# TC37XPD register map
Vendor: Infineon; Series: ATVMC; File version: 100
CPU: other r0p0, little endian, MPU, FPU, vendor SysTick, 4 interrupt priority bits
Registers are 32-bit, read-write, reset 0x0 unless marked. A register's access mark holds for its fields unless they carry their own. Offsets are from the block's base; [hi:lo] are bit positions; lines under a group give offsets from that group; {n}, {i} and the like mark numbered series; 'fields as' and 'values as' point back to an identical list.

## GETH (part 3 of 7)
Base 0xF001D000
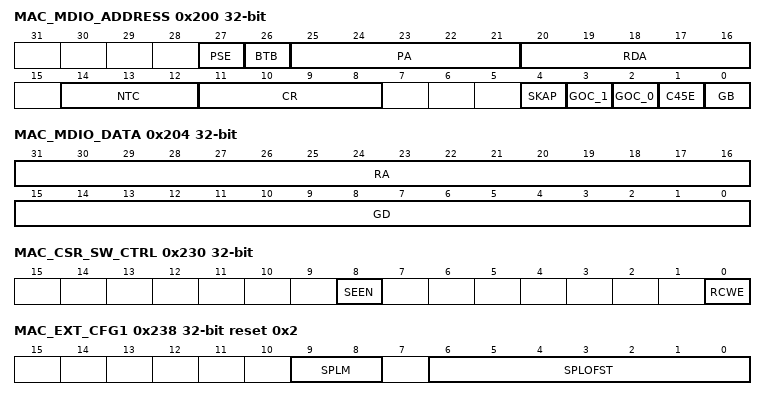
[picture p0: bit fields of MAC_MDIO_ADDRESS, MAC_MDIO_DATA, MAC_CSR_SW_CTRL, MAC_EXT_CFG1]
0x200 MAC_MDIO_ADDRESS — MAC MDIO Address Register resetvalue={Application Reset:0x0}
  [27] PSE — Preamble Suppression Enable PSE. When this bit is set the SMA suppresses the 32 bit preamble and transmits MDIO frames with only 1 preamble bit. When this bit is 0 the MDIO frame always has 32 bits of preamble as defined in the IEEE specifications. Value After Reset 0x0
  [26] BTB — Back to Back transactions BTB. When this bit is set and the NTC has value greater than 0 then the MAC informs the completion of a read or write command at the end of frame transfer before the trailing clocks are transmitted . The software can thus initiate the next command which is executed immediately irrespective of the number trailing clocks generated for the previous frame. When this bit is reset then the read write command completion GB is cleared only after the trailing clocks are generated. In this mode it is ensured that the NTC is always generated after each frame. This bit must not be set when NTC 0. Value After Reset 0x0
  [25:21] PA — Physical Layer Address PA. This field indicates which Clause 22 PHY devices out of 32 devices the MAC is accessing. This field indicates which Clause 45 capable PHYs out of 32 PHYs the MAC is accessing. Value After Reset 0x0
  [20:16] RDA — Register Device Address RDA. These bits select the PHY register in selected Clause 22 PHY device. These bits select the Device MMD in selected Clause 45 capable PHY. Value After Reset 0x0
  [14:12] NTC — Number of Trailing Clocks NTC. This field controls the number of trailing clock cycles generated on gmii mdc o MDC after the end of transmission of MDIO frame. The valid values can be from 0 to 7. Programming the value to 3 h3 indicates that there are additional three clock cycles on the MDC line after the end of MDIO frame transfer. Value After Reset 0x0
  [11:8] CR — CSR Clock Range CR. The CSR Clock Range selection determines the frequency of the MDC clock according to the CSR clock frequency used in your design 0110 0111 Reserved The suggested range of CSR clock frequency applicable for each value when Bit 11 0 ensures that the MDC clock is approximately between 1.0 MHz to 2.5 MHz frequency range. When Bit 11 is set you can achieve a higher frequency of the MDC clock than the frequency limit of 2.5 MHz specified in the IEEE 802.3 and program a clock divider of lower value. For example when CSR clock is of 100 MHz frequency and you program these bits as 1010 the resultant MDC clock is of 12.5 MHz which is above the range specified in IEEE 802.3. Program the following values only if the interfacing chips support faster MDC clocks These bits are not used for accessing RevMII. These bits are read only if the RevMII interface is selected as single PHY interface. Value After Reset 0x0
  [4] SKAP — Skip Address Packet SKAP. When this bit is set the SMA does not send the address packets before read write or post read increment address packets. This bit is valid only when C45E is set. Value After Reset 0x0
  [3] GOC_1 — GMII Operation Command 1 GOC 1. This bit is higher bit of the operation command to the PHY or RevMII GOC 1 and GOC O is encoded as follows 00 Reserved 01 Write 10 Post Read Increment Address for Clause 45 PHY 11 Read When Clause 22 PHY or RevMII is enabled only Write and Read commands are valid. Value After Reset 0x0
  [2] GOC_0 — GMII Operation Command 0 GOC 0. This is the lower bit of the operation command to the PHY or RevMII. When in SMA mode MDIO master this bit along with GOC 1 determines the operation to be performed to the PHY. When only RevMII is selected in configuration this bit is read only and tied to 1. Value After Reset 0x0
  [1] C45E — Clause 45 PHY Enable C45E. When this bit is set Clause 45 capable PHY is connected to MDIO. When this bit is reset Clause 22 capable PHY is connected to MDIO. Value After Reset 0x0
  [0] GB — GMII Busy GB. The application sets this bit to instruct the SMA to initiate a Read or Write access to the MDIO slave. The MAC clears this bit after the MDIO frame transfer is completed. Hence the software must not write or change any of the fields in MAC MDIO Address and MAC MDIO Data registers as long as this bit is set. For write transfers the application must first write 16 bit data in the GDl field and also RA field when C45E is set in MAC MDIO Data register before setting this bit. When C45E is set it should also write into the RA field of MAC MDIO Data register before initiating a read transfer. When a read transfer is completed GB 0 the data read from the PHY register is valid in the GD field of the MAC MDIO Data register. Note Even if the addressed PHY is not present there is no change in the functionality of this bit. Access restriction applies. Setting 1 sets. Self cleared. Setting 0 has no effect. Value After Reset 0x0
0x204 MAC_MDIO_DATA — MAC MDIO Data Register resetvalue={Application Reset:0x0}
  [31:16] RA — Register Address RA. This field is valid only when C45E is set. It contains the Register Address in the PHY to which the MDIO frame is intended for. Value After Reset 0x0
  [15:0] GD — GMII Data GD. This field contains the 16 bit data value read from the PHY or RevMII after a Management Read operation or the 16 bit data value to be written to the PHY or RevMII before a Management Write operation. Value After Reset 0x0
0x230 MAC_CSR_SW_CTRL — MAC CSR Software Controls Register resetvalue={Application Reset:0x0}
  [8] SEEN — Slave Error Response Enable SEEN. When this bit is set the MAC responds with Slave Error for accesses to reserved registers in CSR space. When this bit is reset the MAC responds with Okay response to any register accessed from CSR space. Value After Reset 0x0
  [0] RCWE — Register Clear on Write 1 Enable RCWE . When this bit is set the access mode of some register fields changes to Clear on Write 1 the application needs to set that respective bit to 1 to clear it. When this bit is reset the access mode of these register fields remain as Clear on Read. Value After Reset 0x0
0x238 MAC_EXT_CFG1 reset 0x2 — MAC Extended Configuration Register 1 resetvalue={Application Reset:0x2}
  [9:8] SPLM — Split Mode SPLM. These bits indicate the mode of splitting the incoming Rx packets. They are
  [6:0] SPLOFST — Split Offset SPLOFST. These bits indicate the value of offset from the beginning of Length Type field at which header split should take place when the appropriate SPLM is selected. The reset value of this field is 2 bytes indicating a split at L2 header. Value is in terms ofbytes.
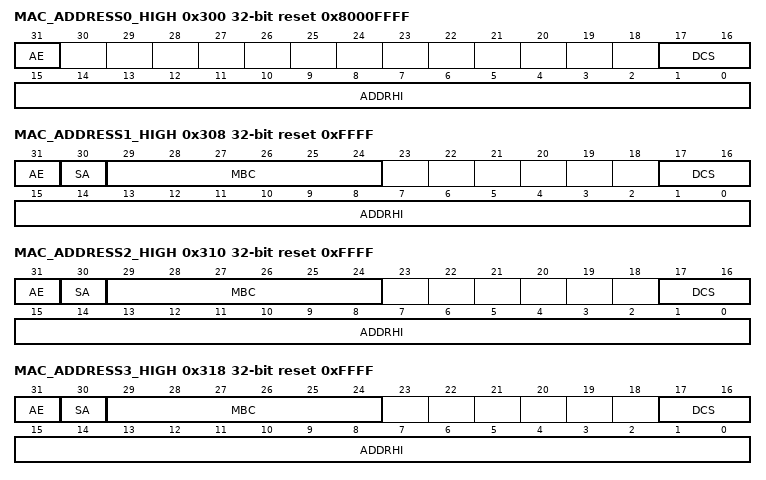
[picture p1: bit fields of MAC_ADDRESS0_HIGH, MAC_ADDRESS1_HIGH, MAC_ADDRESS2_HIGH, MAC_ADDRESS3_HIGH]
0x300 MAC_ADDRESS0_HIGH access per field reset 0x8000FFFF — MAC Address 0 High Register resetvalue={Application Reset:0x08000FFFF}
  [31] AE ro — Address Enable AE. This bit is always set to 1. Value After Reset 0x1
  [17:16] DCS rw — DMA Channel Select DCS. If the PDC bit of MAC Ext Configuration register is not set This field contains the binary representation of the DMA Channel number to which an Rx packet whose DA matches the MAC Address0 content is routed. If the PDC bit of MAC Ext Configuration register is set This field contains the one hot representation of one or more DMA Channel numbers to which an Rx packet whose DA matches the MAC Address0 content is routed.
  [15:0] ADDRHI rw — MAC Address0 47 32 ADDRHI. This field contains the upper 16 bits 47 32 of the first 6 byte MAC address. The MAC uses this field for filtering the received packets and inserting the MAC address in the Transmit Flow Control Pause Packets. Value After Reset 0xffff
0x304 MAC_ADDRESS0_LOW reset 0xFFFFFFFF — MAC Address 0 Low Register resetvalue={Application Reset:0x0FFFFFFFF}
  [31:0] ADDRLO — MAC Address0 31 0 ADDRLO. This field contains the lower 32 bits of the first 6 byte MAC address. The MAC uses this field for filtering the received packets and inserting the MAC address in the Transmit Flow Control Pause Packets. Value After Reset 0xffffffff
0x308 MAC_ADDRESS1_HIGH reset 0xFFFF — MAC Address 31 High Register resetvalue={Application Reset:0x0FFFF}
  [31] AE — Address Enable AE. When this bit is set the address filter module uses the second MAC address for perfect filtering. When this bit is reset the address filter module ignores the address for filtering. Value After Reset 0x0
  [30] SA — Source Address SA. When this bit is set the MAC Address1 47 0 is used to compare with the SA fields of the received packet. When this bit is reset the MAC Address1 47 0 is used to compare with the DA fields of the received packet. Value After Reset 0x0
  [29:24] MBC — Mask Byte Control MBC. These bits are mask control bits for comparing each of the MAC Address bytes. When set high the MAC does not compare the corresponding byte of received DA or SA with the contents of MAC Address1 registers. Each bit controls the masking of the bytes as follows Bit 29 Register 194 15 8 Bit 28 Register 194 7 0 Bit 27 Register 195 31 24 Bit 24 Register 195 7 0 You can filter a group of addresses known as group address filtering by masking one or more bytes of the address. Value After Reset 0x0
  [17:16] DCS — DMA Channel Select DCS. If the PDC bit of MAC Ext Configuration register is not set This field contains the binary representation of the DMA Channel number to which an Rx packet whose DA matches the MAC Address0 content is routed. If the PDC bit of MAC Ext Configuration register is set This field contains the one hot representation of one or more DMA Channel numbers to which an Rx packet whose DA matches the MAC Address0 content is routed.
  [15:0] ADDRHI — MAC Address1 47 32 ADDRHI. This field contains the upper 16 bits 47 32 of the second 6 byte MAC address. Value After Reset 0xffff
0x30C MAC_ADDRESS1_LOW reset 0xFFFFFFFF — MAC Address 31 Low Register resetvalue={Application Reset:0x0FFFFFFFF}
  [31:0] ADDRLO — MAC Address1 31 0 ADDRLO. This field contains the lower 32 bits of second 6 byte MAC address. The content of this field is undefined until loaded by the application after the initialization process. Value After Reset 0xffffffff
0x310 MAC_ADDRESS2_HIGH reset 0xFFFF — MAC Address 31 High Register resetvalue={Application Reset:0x0FFFF}
  fields as MAC_ADDRESS1_HIGH
0x314 MAC_ADDRESS2_LOW reset 0xFFFFFFFF — MAC Address 31 Low Register resetvalue={Application Reset:0x0FFFFFFFF}
  fields as MAC_ADDRESS1_LOW
0x318 MAC_ADDRESS3_HIGH reset 0xFFFF — MAC Address 31 High Register resetvalue={Application Reset:0x0FFFF}
  fields as MAC_ADDRESS1_HIGH
0x31C MAC_ADDRESS3_LOW reset 0xFFFFFFFF — MAC Address 31 Low Register resetvalue={Application Reset:0x0FFFFFFFF}
  fields as MAC_ADDRESS1_LOW
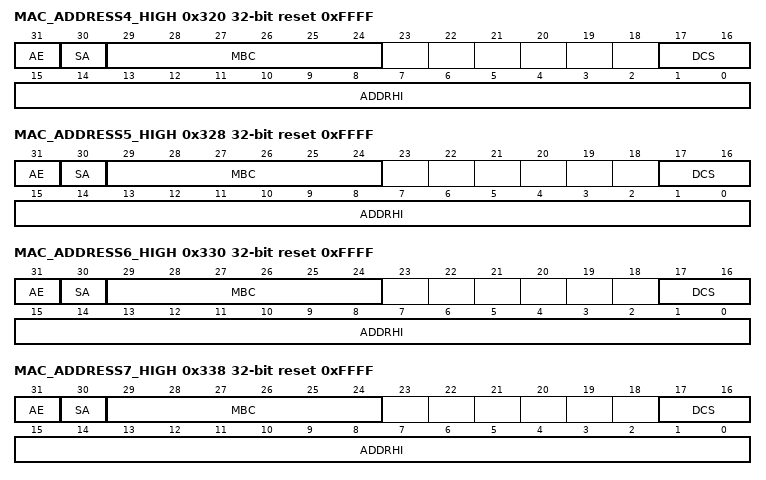
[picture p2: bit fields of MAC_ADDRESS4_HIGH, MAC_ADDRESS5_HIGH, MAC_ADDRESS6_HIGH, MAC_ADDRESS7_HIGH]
0x320 MAC_ADDRESS4_HIGH reset 0xFFFF — MAC Address 31 High Register resetvalue={Application Reset:0x0FFFF}
  fields as MAC_ADDRESS1_HIGH
0x324 MAC_ADDRESS4_LOW reset 0xFFFFFFFF — MAC Address 31 Low Register resetvalue={Application Reset:0x0FFFFFFFF}
  fields as MAC_ADDRESS1_LOW
0x328 MAC_ADDRESS5_HIGH reset 0xFFFF — MAC Address 31 High Register resetvalue={Application Reset:0x0FFFF}
  fields as MAC_ADDRESS1_HIGH
0x32C MAC_ADDRESS5_LOW reset 0xFFFFFFFF — MAC Address 31 Low Register resetvalue={Application Reset:0x0FFFFFFFF}
  fields as MAC_ADDRESS1_LOW
0x330 MAC_ADDRESS6_HIGH reset 0xFFFF — MAC Address 31 High Register resetvalue={Application Reset:0x0FFFF}
  fields as MAC_ADDRESS1_HIGH
0x334 MAC_ADDRESS6_LOW reset 0xFFFFFFFF — MAC Address 31 Low Register resetvalue={Application Reset:0x0FFFFFFFF}
  fields as MAC_ADDRESS1_LOW
0x338 MAC_ADDRESS7_HIGH reset 0xFFFF — MAC Address 31 High Register resetvalue={Application Reset:0x0FFFF}
  fields as MAC_ADDRESS1_HIGH
0x33C MAC_ADDRESS7_LOW reset 0xFFFFFFFF — MAC Address 31 Low Register resetvalue={Application Reset:0x0FFFFFFFF}
  fields as MAC_ADDRESS1_LOW
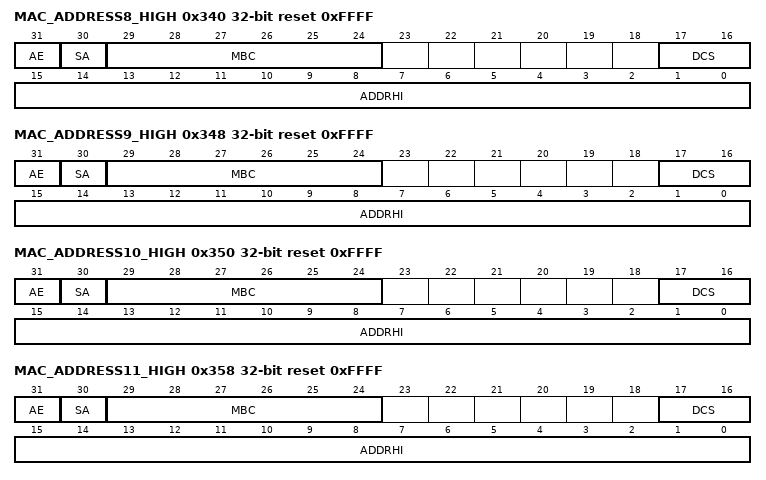
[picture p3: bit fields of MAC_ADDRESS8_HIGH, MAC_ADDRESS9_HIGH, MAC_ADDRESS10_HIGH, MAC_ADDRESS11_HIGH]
0x340 MAC_ADDRESS8_HIGH reset 0xFFFF — MAC Address 31 High Register resetvalue={Application Reset:0x0FFFF}
  fields as MAC_ADDRESS1_HIGH
0x344 MAC_ADDRESS8_LOW reset 0xFFFFFFFF — MAC Address 31 Low Register resetvalue={Application Reset:0x0FFFFFFFF}
  fields as MAC_ADDRESS1_LOW
0x348 MAC_ADDRESS9_HIGH reset 0xFFFF — MAC Address 31 High Register resetvalue={Application Reset:0x0FFFF}
  fields as MAC_ADDRESS1_HIGH
0x34C MAC_ADDRESS9_LOW reset 0xFFFFFFFF — MAC Address 31 Low Register resetvalue={Application Reset:0x0FFFFFFFF}
  fields as MAC_ADDRESS1_LOW
0x350 MAC_ADDRESS10_HIGH reset 0xFFFF — MAC Address 31 High Register resetvalue={Application Reset:0x0FFFF}
  fields as MAC_ADDRESS1_HIGH
0x354 MAC_ADDRESS10_LOW reset 0xFFFFFFFF — MAC Address 31 Low Register resetvalue={Application Reset:0x0FFFFFFFF}
  fields as MAC_ADDRESS1_LOW
0x358 MAC_ADDRESS11_HIGH reset 0xFFFF — MAC Address 31 High Register resetvalue={Application Reset:0x0FFFF}
  fields as MAC_ADDRESS1_HIGH
0x35C MAC_ADDRESS11_LOW reset 0xFFFFFFFF — MAC Address 31 Low Register resetvalue={Application Reset:0x0FFFFFFFF}
  fields as MAC_ADDRESS1_LOW
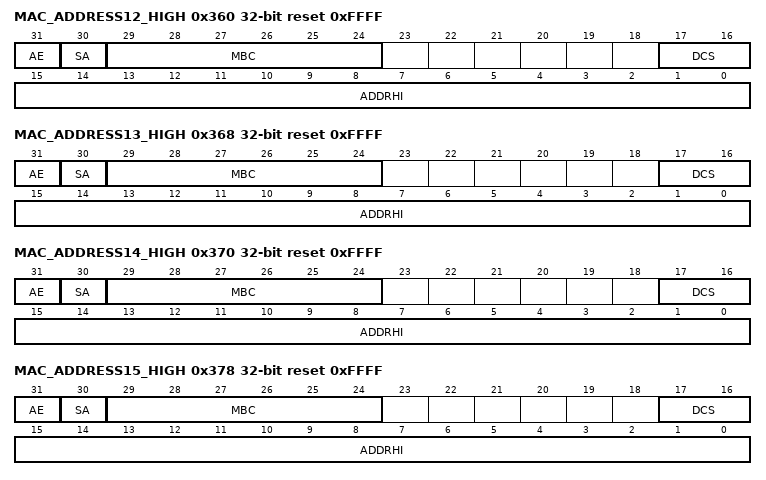
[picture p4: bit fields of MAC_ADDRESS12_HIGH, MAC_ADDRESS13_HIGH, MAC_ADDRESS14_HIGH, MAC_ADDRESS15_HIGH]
0x360 MAC_ADDRESS12_HIGH reset 0xFFFF — MAC Address 31 High Register resetvalue={Application Reset:0x0FFFF}
  fields as MAC_ADDRESS1_HIGH
0x364 MAC_ADDRESS12_LOW reset 0xFFFFFFFF — MAC Address 31 Low Register resetvalue={Application Reset:0x0FFFFFFFF}
  fields as MAC_ADDRESS1_LOW
0x368 MAC_ADDRESS13_HIGH reset 0xFFFF — MAC Address 31 High Register resetvalue={Application Reset:0x0FFFF}
  fields as MAC_ADDRESS1_HIGH
0x36C MAC_ADDRESS13_LOW reset 0xFFFFFFFF — MAC Address 31 Low Register resetvalue={Application Reset:0x0FFFFFFFF}
  fields as MAC_ADDRESS1_LOW
0x370 MAC_ADDRESS14_HIGH reset 0xFFFF — MAC Address 31 High Register resetvalue={Application Reset:0x0FFFF}
  fields as MAC_ADDRESS1_HIGH
0x374 MAC_ADDRESS14_LOW reset 0xFFFFFFFF — MAC Address 31 Low Register resetvalue={Application Reset:0x0FFFFFFFF}
  fields as MAC_ADDRESS1_LOW
0x378 MAC_ADDRESS15_HIGH reset 0xFFFF — MAC Address 31 High Register resetvalue={Application Reset:0x0FFFF}
  fields as MAC_ADDRESS1_HIGH
0x37C MAC_ADDRESS15_LOW reset 0xFFFFFFFF — MAC Address 31 Low Register resetvalue={Application Reset:0x0FFFFFFFF}
  fields as MAC_ADDRESS1_LOW
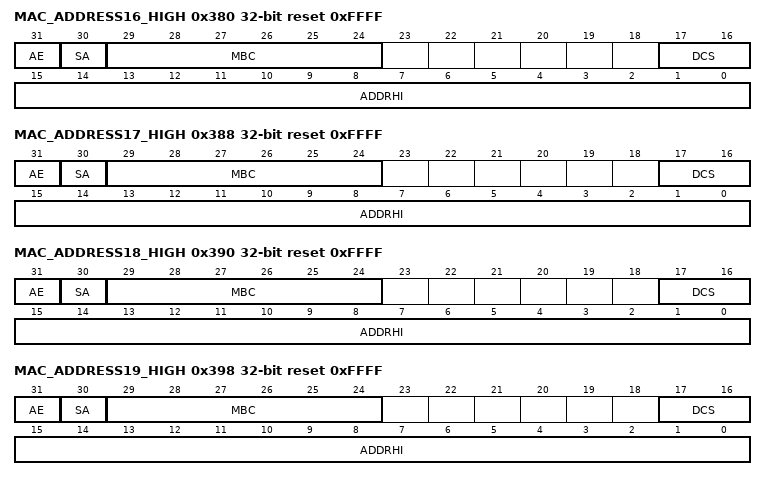
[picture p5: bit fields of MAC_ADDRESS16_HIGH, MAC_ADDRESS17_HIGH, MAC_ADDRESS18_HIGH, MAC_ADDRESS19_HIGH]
0x380 MAC_ADDRESS16_HIGH reset 0xFFFF — MAC Address 31 High Register resetvalue={Application Reset:0x0FFFF}
  fields as MAC_ADDRESS1_HIGH
0x384 MAC_ADDRESS16_LOW reset 0xFFFFFFFF — MAC Address 31 Low Register resetvalue={Application Reset:0x0FFFFFFFF}
  fields as MAC_ADDRESS1_LOW
0x388 MAC_ADDRESS17_HIGH reset 0xFFFF — MAC Address 31 High Register resetvalue={Application Reset:0x0FFFF}
  fields as MAC_ADDRESS1_HIGH
0x38C MAC_ADDRESS17_LOW reset 0xFFFFFFFF — MAC Address 31 Low Register resetvalue={Application Reset:0x0FFFFFFFF}
  fields as MAC_ADDRESS1_LOW
0x390 MAC_ADDRESS18_HIGH reset 0xFFFF — MAC Address 31 High Register resetvalue={Application Reset:0x0FFFF}
  fields as MAC_ADDRESS1_HIGH
0x394 MAC_ADDRESS18_LOW reset 0xFFFFFFFF — MAC Address 31 Low Register resetvalue={Application Reset:0x0FFFFFFFF}
  fields as MAC_ADDRESS1_LOW
0x398 MAC_ADDRESS19_HIGH reset 0xFFFF — MAC Address 31 High Register resetvalue={Application Reset:0x0FFFF}
  fields as MAC_ADDRESS1_HIGH
0x39C MAC_ADDRESS19_LOW reset 0xFFFFFFFF — MAC Address 31 Low Register resetvalue={Application Reset:0x0FFFFFFFF}
  fields as MAC_ADDRESS1_LOW
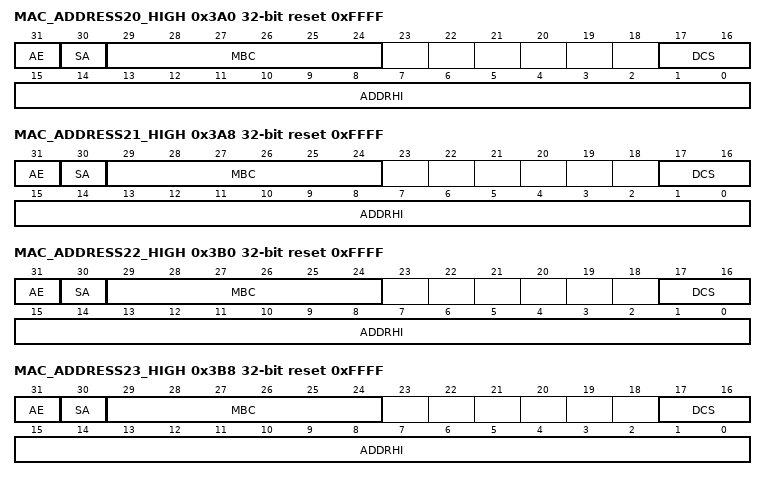
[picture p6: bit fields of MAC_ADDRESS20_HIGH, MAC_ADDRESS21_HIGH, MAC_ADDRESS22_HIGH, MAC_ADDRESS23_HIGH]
0x3A0 MAC_ADDRESS20_HIGH reset 0xFFFF — MAC Address 31 High Register resetvalue={Application Reset:0x0FFFF}
  fields as MAC_ADDRESS1_HIGH
0x3A4 MAC_ADDRESS20_LOW reset 0xFFFFFFFF — MAC Address 31 Low Register resetvalue={Application Reset:0x0FFFFFFFF}
  fields as MAC_ADDRESS1_LOW
0x3A8 MAC_ADDRESS21_HIGH reset 0xFFFF — MAC Address 31 High Register resetvalue={Application Reset:0x0FFFF}
  fields as MAC_ADDRESS1_HIGH
0x3AC MAC_ADDRESS21_LOW reset 0xFFFFFFFF — MAC Address 31 Low Register resetvalue={Application Reset:0x0FFFFFFFF}
  fields as MAC_ADDRESS1_LOW
0x3B0 MAC_ADDRESS22_HIGH reset 0xFFFF — MAC Address 31 High Register resetvalue={Application Reset:0x0FFFF}
  fields as MAC_ADDRESS1_HIGH
0x3B4 MAC_ADDRESS22_LOW reset 0xFFFFFFFF — MAC Address 31 Low Register resetvalue={Application Reset:0x0FFFFFFFF}
  fields as MAC_ADDRESS1_LOW
0x3B8 MAC_ADDRESS23_HIGH reset 0xFFFF — MAC Address 31 High Register resetvalue={Application Reset:0x0FFFF}
  fields as MAC_ADDRESS1_HIGH
0x3BC MAC_ADDRESS23_LOW reset 0xFFFFFFFF — MAC Address 31 Low Register resetvalue={Application Reset:0x0FFFFFFFF}
  fields as MAC_ADDRESS1_LOW
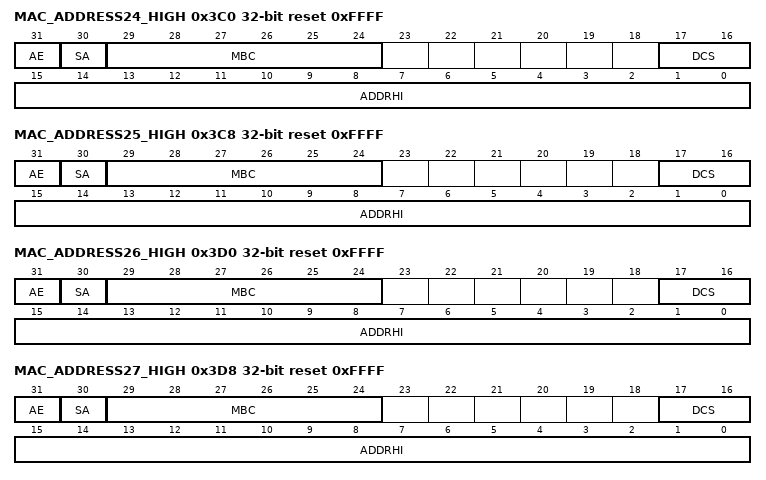
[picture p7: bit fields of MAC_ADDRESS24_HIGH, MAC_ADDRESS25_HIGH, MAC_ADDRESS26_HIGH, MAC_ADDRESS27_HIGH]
0x3C0 MAC_ADDRESS24_HIGH reset 0xFFFF — MAC Address 31 High Register resetvalue={Application Reset:0x0FFFF}
  fields as MAC_ADDRESS1_HIGH
0x3C4 MAC_ADDRESS24_LOW reset 0xFFFFFFFF — MAC Address 31 Low Register resetvalue={Application Reset:0x0FFFFFFFF}
  fields as MAC_ADDRESS1_LOW
0x3C8 MAC_ADDRESS25_HIGH reset 0xFFFF — MAC Address 31 High Register resetvalue={Application Reset:0x0FFFF}
  fields as MAC_ADDRESS1_HIGH
0x3CC MAC_ADDRESS25_LOW reset 0xFFFFFFFF — MAC Address 31 Low Register resetvalue={Application Reset:0x0FFFFFFFF}
  fields as MAC_ADDRESS1_LOW
0x3D0 MAC_ADDRESS26_HIGH reset 0xFFFF — MAC Address 31 High Register resetvalue={Application Reset:0x0FFFF}
  fields as MAC_ADDRESS1_HIGH
0x3D4 MAC_ADDRESS26_LOW reset 0xFFFFFFFF — MAC Address 31 Low Register resetvalue={Application Reset:0x0FFFFFFFF}
  fields as MAC_ADDRESS1_LOW
0x3D8 MAC_ADDRESS27_HIGH reset 0xFFFF — MAC Address 31 High Register resetvalue={Application Reset:0x0FFFF}
  fields as MAC_ADDRESS1_HIGH
0x3DC MAC_ADDRESS27_LOW reset 0xFFFFFFFF — MAC Address 31 Low Register resetvalue={Application Reset:0x0FFFFFFFF}
  fields as MAC_ADDRESS1_LOW
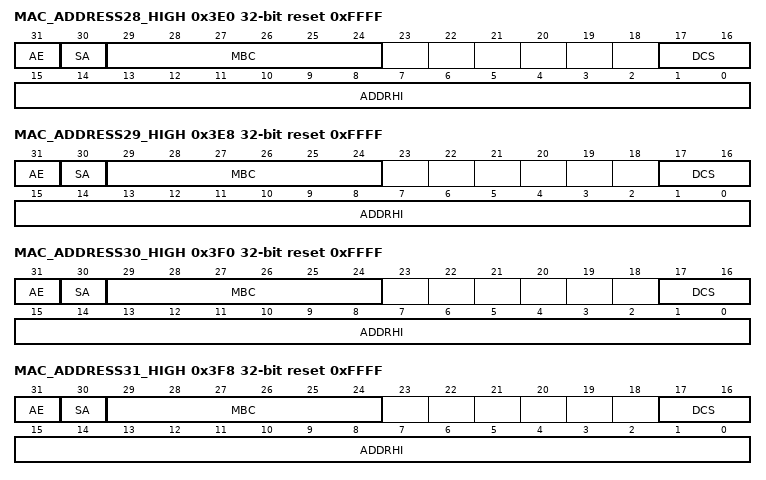
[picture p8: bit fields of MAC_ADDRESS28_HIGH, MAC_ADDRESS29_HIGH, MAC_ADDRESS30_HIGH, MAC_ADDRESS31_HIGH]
0x3E0 MAC_ADDRESS28_HIGH reset 0xFFFF — MAC Address 31 High Register resetvalue={Application Reset:0x0FFFF}
  fields as MAC_ADDRESS1_HIGH
0x3E4 MAC_ADDRESS28_LOW reset 0xFFFFFFFF — MAC Address 31 Low Register resetvalue={Application Reset:0x0FFFFFFFF}
  fields as MAC_ADDRESS1_LOW
0x3E8 MAC_ADDRESS29_HIGH reset 0xFFFF — MAC Address 31 High Register resetvalue={Application Reset:0x0FFFF}
  fields as MAC_ADDRESS1_HIGH
0x3EC MAC_ADDRESS29_LOW reset 0xFFFFFFFF — MAC Address 31 Low Register resetvalue={Application Reset:0x0FFFFFFFF}
  fields as MAC_ADDRESS1_LOW
0x3F0 MAC_ADDRESS30_HIGH reset 0xFFFF — MAC Address 31 High Register resetvalue={Application Reset:0x0FFFF}
  fields as MAC_ADDRESS1_HIGH
0x3F4 MAC_ADDRESS30_LOW reset 0xFFFFFFFF — MAC Address 31 Low Register resetvalue={Application Reset:0x0FFFFFFFF}
  fields as MAC_ADDRESS1_LOW
0x3F8 MAC_ADDRESS31_HIGH reset 0xFFFF — MAC Address 31 High Register resetvalue={Application Reset:0x0FFFF}
  fields as MAC_ADDRESS1_HIGH
0x3FC MAC_ADDRESS31_LOW reset 0xFFFFFFFF — MAC Address 31 Low Register resetvalue={Application Reset:0x0FFFFFFFF}
  fields as MAC_ADDRESS1_LOW
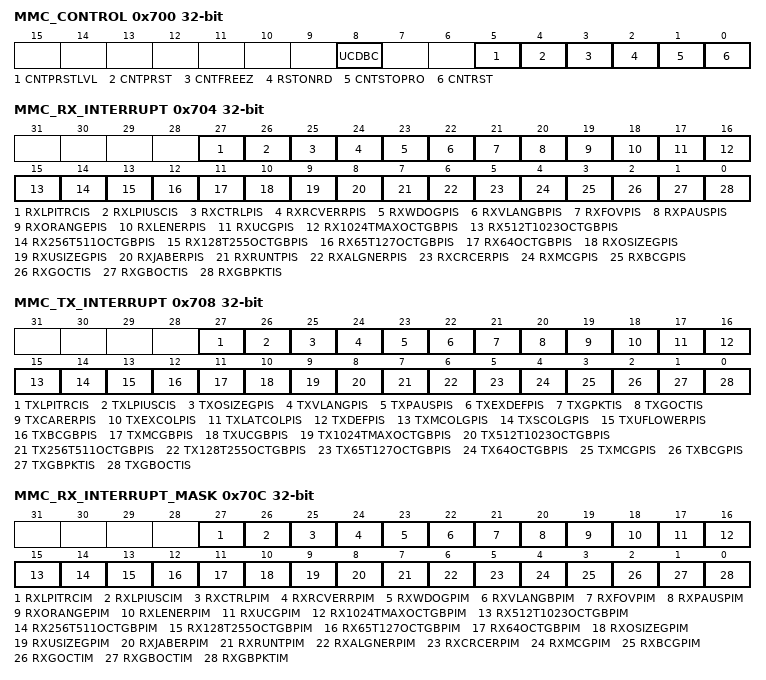
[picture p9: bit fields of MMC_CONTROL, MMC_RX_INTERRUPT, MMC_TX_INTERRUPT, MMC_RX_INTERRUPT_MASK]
0x700 MMC_CONTROL — MMC Control Register resetvalue={Application Reset:0x0}
  [8] UCDBC — Update MMC Counters for Dropped Broadcast Packets UCDBC. When set the MAC updates all related MMC Counters for Broadcast packets that are dropped because of the setting of the DBF bit of MAC Packet Filter register. When reset the MMC Counters are not updated for dropped Broadcast packets. Value After Reset 0x0
  [5] CNTPRSTLVL — Full Half Preset CNTPRSTLVL. When this bit is low and the CNTPRST bit is set all MMC counters get preset to almost half value. All octet counters get preset to 0x7FFF F800 Half 2KBytes and all packet counters gets preset to 0x7FFF FFF0 Half 16 . When this bit is high and the CNTPRST bit is set all MMC counters get preset to almost full value. All octet counters get preset to 0xFFFF F800 Full 2KBytes and all packet counters gets preset to 0xFFFF FFF0 Full 16 . For 16 bit counters the almost half preset values are 0x7800 and 0x7FF0 for the respective octet and packet counters. Similarly the almost full preset values for the 16 bit counters are 0xF800 and 0xFFF0. Value After Reset 0x0
  [4] CNTPRST — Counters Preset CNTPRST. When this bit is set all counters are initialized or preset to almost full or almost half according to the CNTPRSTLVL bit. This bit is cleared automatically after 1 clock cycle. This bit along with the CNTPRSTLVL bit is useful for debugging and testing the assertion of interrupts because of MMC counter becoming half full or full. Access restriction applies. Self cleared. Setting 0 clears. Setting 1 sets. Value After Reset 0x0
  [3] CNTFREEZ — MMC Counter Freeze CNTFREEZ. When this bit is set it freezes all MMC counters to their current value. Until this bit is reset to 0 no MMC counter is updated because of any transmitted or received packet. If any MMC counter is read with the Reset on Read bit set then that counter is also cleared in this mode. Value After Reset 0x0
  [2] RSTONRD — Reset on Read RSTONRD. When this bit is set the MMC counters are reset to zero after Read self clearing after reset . The counters are cleared when the least significant byte lane Bits 7 0 is read. Value After Reset 0x0
  [1] CNTSTOPRO — Counter Stop Rollover CNTSTOPRO. When this bit is set the counter does not roll over to zero after reaching the maximum value. Value After Reset 0x0
  [0] CNTRST — Counters Reset CNTRST. When this bit is set all counters are reset. This bit is cleared automatically after 1 clock cycle. Access restriction applies. Self cleared. Setting 0 clears. Setting 1 sets. Value After Reset 0x0
0x704 MMC_RX_INTERRUPT ro — MMC Receive Interrupts Register resetvalue={Application Reset:0x0}
  [27] RXLPITRCIS — MMC Receive LPI transition counter interrupt status RXLPITRCIS. This bit is set when the Rx LPI Tran Cntr counter reaches half of the maximum value or the maximum value. Access restriction applies. Clears on read. Self set to 1 on internal event. Value After Reset 0x0
  [26] RXLPIUSCIS — MMC Receive LPI microsecond counter interrupt status RXLPIUSCIS. This bit is set when the Rx LPI USEC Cntr counter reaches half of the maximum value or the maximum value. Access restriction applies. Clears on read. Self set to 1 on internal event. Value After Reset 0x0
  [25] RXCTRLPIS — MMC Receive Control Packet Counter Interrupt Status RXCTRLPIS. This bit is set when the rxctrlpackets g counter reaches half of the maximum value or the maximum value. Access restriction applies. Clears on read. Self set to 1 on internal event. Value After Reset 0x0
  [24] RXRCVERRPIS — MMC Receive Error Packet Counter Interrupt Status RXRCVERRPIS. This bit is set when the rxrcverror counter reaches half of the maximum value or the maximum value. Access restriction applies. Clears on read. Self set to 1 on internal event. Value After Reset 0x0
  [23] RXWDOGPIS — MMC Receive Watchdog Error Packet Counter Interrupt Status RXWDOGPIS. This bit is set when the rxwatchdog error counter reaches half of the maximum value or the maximum value. Access restriction applies. Clears on read. Self set to 1 on internal event. Value After Reset 0x0
  [22] RXVLANGBPIS — MMC Receive VLAN Good Bad Packet Counter Interrupt Status RXVLANGBPIS. This bit is set when the rxvlanpackets gb counter reaches half of the maximum value or the maximum value. Access restriction applies. Clears on read. Self set to 1 on internal event. Value After Reset 0x0
  [21] RXFOVPIS — MMC Receive FIFO Overflow Packet Counter Interrupt Status RXFOVPIS. This bit is set when the rxfifooverflow counter reaches half of the maximum value or the maximum value. Access restriction applies. Clears on read. Self set to 1 on internal event. Value After Reset 0x0
  [20] RXPAUSPIS — MMC Receive Pause Packet Counter Interrupt Status RXPAUSPIS. This bit is set when the rxpausepackets counter reaches half of the maximum value or the maximum value. Access restriction applies. Clears on read. Self set to 1 on internal event. Value After Reset 0x0
  [19] RXORANGEPIS — MMC Receive Out Of Range Error Packet Counter Interrupt Status. RXORANGEPIS. This bit is set when the rxoutofrangetype counter reaches half of the maximum value or the maximum value. Access restriction applies. Clears on read. Self set to 1 on internal event. Value After Reset 0x0
  [18] RXLENERPIS — MMC Receive Length Error Packet Counter Interrupt Status RXLENERPIS. This bit is set when the rxlengtherror counter reaches half of the maximum value or the maximum value. Access restriction applies. Clears on read. Self set to 1 on internal event. Value After Reset 0x0
  [17] RXUCGPIS — MMC Receive Unicast Good Packet Counter Interrupt Status RXUCGPIS. This bit is set when the rxunicastpackets g counter reaches half of the maximum value or the maximum value. Access restriction applies. Clears on read. Self set to 1 on internal event. Value After Reset 0x0
  [16] RX1024TMAXOCTGBPIS — MMC Receive 1024 to Maximum Octet Good Bad Packet Counter Interrupt Status RX1024TMAXOCTGBPIS. This bit is set when the rx1024tomaxoctets gb counter reaches half of the maximum value or the maximum value. Access restriction applies. Clears on read. Self set to 1 on internal event. Value After Reset 0x0
  [15] RX512T1023OCTGBPIS — MMC Receive 512 to 1023 Octet Good Bad Packet Counter Interrupt Status RX512T1023OCTGBPIS. This bit is set when the rx512to1023octets gb counter reaches half of the maximum value or the maximum value. Access restriction applies. Clears on read. Self set to 1 on internal event. Value After Reset 0x0
  [14] RX256T511OCTGBPIS — MMC Receive 256 to 511 Octet Good Bad Packet Counter Interrupt Status RX256T511OCTGBPIS. This bit is set when the rx256to511octets gb counter reaches half of the maximum value or the maximum value. Access restriction applies. Clears on read. Self set to 1 on internal event. Value After Reset 0x0
  [13] RX128T255OCTGBPIS — MMC Receive 128 to 255 Octet Good Bad Packet Counter Interrupt Status RX128T255OCTGBPIS. This bit is set when the rx128to255octets gb counter reaches half of the maximum value or the maximum value. Access restriction applies. Clears on read. Self set to 1 on internal event. Value After Reset 0x0
  [12] RX65T127OCTGBPIS — MMC Receive 65 to 127 Octet Good Bad Packet Counter Interrupt Status RX65T127OCTGBPIS. This bit is set when the rx65to127octets gb counter reaches half of the maximum value or the maximum value. Access restriction applies. Clears on read. Self set to 1 on internal event. Value After Reset 0x0
  [11] RX64OCTGBPIS — MMC Receive 64 Octet Good Bad Packet Counter Interrupt Status RX64OCTGBPIS. This bit is set when the rx64octets gb counter reaches half of the maximum value or the maximum value. Access restriction applies. Clears on read. Self set to 1 on internal event. Value After Reset 0x0
  [10] RXOSIZEGPIS — MMC Receive Oversize Good Packet Counter Interrupt Status RXOSIZEGPIS. This bit is set when the rxoversize g counter reaches half of the maximum value or the maximum value. Access restriction applies. Clears on read. Self set to 1 on internal event. Value After Reset 0x0
  [9] RXUSIZEGPIS — MMC Receive Undersize Good Packet Counter Interrupt Status RXUSIZEGPIS. This bit is set when the rxundersize g counter reaches half of the maximum value or the maximum value. Access restriction applies. Clears on read. Self set to 1 on internal event. Value After Reset 0x0
  [8] RXJABERPIS — MMC Receive Jabber Error Packet Counter Interrupt Status RXJABERPIS. This bit is set when the rxjabbererror counter reaches half of the maximum value or the maximum value. Access restriction applies. Clears on read. Self set to 1 on internal event. Value After Reset 0x0
  [7] RXRUNTPIS — MMC Receive Runt Packet Counter Interrupt Status RXRUNTPIS. This bit is set when the rxrunterror counter reaches half of the maximum value or the maximum value. Access restriction applies. Clears on read. Self set to 1 on internal event. Value After Reset 0x0
  [6] RXALGNERPIS — MMC Receive Alignment Error Packet Counter Interrupt Status RXALGNERPIS. This bit is set when the rxalignmenterror counter reaches half of the maximum value or the maximum value. Access restriction applies. Clears on read. Self set to 1 on internal event. Value After Reset 0x0
  [5] RXCRCERPIS — MMC Receive CRC Error Packet Counter Interrupt Status RXCRCERPIS. This bit is set when the rxcrcerror counter reaches half of the maximum value or the maximum value. Access restriction applies. Clears on read. Self set to 1 on internal event. Value After Reset 0x0
  [4] RXMCGPIS — MMC Receive Multicast Good Packet Counter Interrupt Status RXMCGPIS. This bit is set when the rxmulticastpackets g counter reaches half of the maximum value or the maximum value. Access restriction applies. Clears on read. Self set to 1 on internal event. Value After Reset 0x0
  [3] RXBCGPIS — MMC Receive Broadcast Good Packet Counter Interrupt Status RXBCGPIS. This bit is set when the rxbroadcastpackets g counter reaches half of the maximum value or the maximum value. Access restriction applies. Clears on read. Self set to 1 on internal event. Value After Reset 0x0
  [2] RXGOCTIS — MMC Receive Good Octet Counter Interrupt Status RXGOCTIS. This bit is set when the rxoctetcount g counter reaches half of the maximum value or the maximum value. Access restriction applies. Clears on read. Self set to 1 on internal event. Value After Reset 0x0
  [1] RXGBOCTIS — MMC Receive Good Bad Octet Counter Interrupt Status RXGBOCTIS. This bit is set when the rxoctetcount gb counter reaches half of the maximum value or the maximum value. Access restriction applies. Clears on read. Self set to 1 on internal event. Value After Reset 0x0
  [0] RXGBPKTIS — MMC Receive Good Bad Packet Counter Interrupt Status RXGBPKTIS. This bit is set when the rxpacketcount gb counter reaches half of the maximum value or the maximum value. Access restriction applies. Clears on read. Self set to 1 on internal event. Value After Reset 0x0
0x708 MMC_TX_INTERRUPT ro — MMC Transmit Interrupts Register resetvalue={Application Reset:0x0}
  [27] TXLPITRCIS — MMC Transmit LPI transition counter interrupt status TXLPITRCIS. This bit is set when the Tx LPI Tran Cntr counter reaches half of the maximum value or the maximum value. Access restriction applies. Clears on read. Self set to 1 on internal event. Value After Reset 0x0
  [26] TXLPIUSCIS — MMC Transmit LPI microsecond counter interrupt status TXLPIUSCIS. This bit is set when the Tx LPI USEC Cntr counter reaches half of the maximum value or the maximum value. Access restriction applies. Clears on read. Self set to 1 on internal event. Value After Reset 0x0
  [25] TXOSIZEGPIS — MMC Transmit Oversize Good Packet Counter Interrupt Status TXOSIZEGPIS. This bit is set when the txoversize g counter reaches half of the maximum value or the maximum value. Access restriction applies. Clears on read. Self set to 1 on internal event. Value After Reset 0x0
  [24] TXVLANGPIS — MMC Transmit VLAN Good Packet Counter Interrupt Status TXVLANGPIS. This bit is set when the txvlanpackets g counter reaches half of the maximum value or the maximum value. Access restriction applies. Clears on read. Self set to 1 on internal event. Value After Reset 0x0
  [23] TXPAUSPIS — MMC Transmit Pause Packet Counter Interrupt Status TXPAUSPIS. This bit is set when the txpausepacketserror counter reaches half of the maximum value or the maximum value. Access restriction applies. Clears on read. Self set to 1 on internal event. Value After Reset 0x0
  [22] TXEXDEFPIS — MMC Transmit Excessive Deferral Packet Counter Interrupt Status TXEXDEFPIS. This bit is set when the txexcessdef counter reaches half of the maximum value or the maximum value. Access restriction applies. Clears on read. Self set to 1 on internal event. Value After Reset 0x0
  [21] TXGPKTIS — MMC Transmit Good Packet Counter Interrupt Status TXGPKTIS. This bit is set when the txpacketcount g counter reaches half of the maximum value or the maximum value. Access restriction applies. Clears on read. Self set to 1 on internal event. Value After Reset 0x0
  [20] TXGOCTIS — MMC Transmit Good Octet Counter Interrupt Status TXGOCTIS. This bit is set when the txoctetcount g counter reaches half of the maximum value or the maximum value. Access restriction applies. Clears on read. Self set to 1 on internal event. Value After Reset 0x0
  [19] TXCARERPIS — MMC Transmit Carrier Error Packet Counter Interrupt Status TXCARERPIS. This bit is set when the txcarriererror counter reaches half of the maximum value or the maximum value. Access restriction applies. Clears on read. Self set to 1 on internal event. Value After Reset 0x0
  [18] TXEXCOLPIS — MMC Transmit Excessive Collision Packet Counter Interrupt Status TXEXCOLPIS. This bit is set when the txexesscol counter reaches half of the maximum value or the maximum value. Access restriction applies. Clears on read. Self set to 1 on internal event. Value After Reset 0x0
  [17] TXLATCOLPIS — MMC Transmit Late Collision Packet Counter Interrupt Status TXLATCOLPIS. This bit is set when the txlatecol counter reaches half of the maximum value or the maximum value. Access restriction applies. Clears on read. Self set to 1 on internal event. Value After Reset 0x0
  [16] TXDEFPIS — MMC Transmit Deferred Packet Counter Interrupt Status TXDEFPIS. This bit is set when the txdeferred counter reaches half of the maximum value or the maximum value. Access restriction applies. Clears on read. Self set to 1 on internal event. Value After Reset 0x0
  [15] TXMCOLGPIS — MMC Transmit Multiple Collision Good Packet Counter Interrupt Status TXMCOLGPIS. This bit is set when the txmulticol g counter reaches half of the maximum value or the maximum value. Access restriction applies. Clears on read. Self set to 1 on internal event. Value After Reset 0x0
  [14] TXSCOLGPIS — MMC Transmit Single Collision Good Packet Counter Interrupt Status TXSCOLGPIS. This bit is set when the txsinglecol g counter reaches half of the maximum value or the maximum value. Access restriction applies. Clears on read. Self set to 1 on internal event. Value After Reset 0x0
  [13] TXUFLOWERPIS — MMC Transmit Underflow Error Packet Counter Interrupt Status TXUFLOWERPIS. This bit is set when the txunderflowerror counter reaches half of the maximum value or the maximum value. Access restriction applies. Clears on read. Self set to 1 on internal event. Value After Reset 0x0
  [12] TXBCGBPIS — MMC Transmit Broadcast Good Bad Packet Counter Interrupt Status TXBCGBPIS. This bit is set when the txbroadcastpackets gb counter reaches half of the maximum value or the maximum value. Access restriction applies. Clears on read. Self set to 1 on internal event. Value After Reset 0x0
  [11] TXMCGBPIS — MMC Transmit Multicast Good Bad Packet Counter Interrupt Status TXMCGBPIS. The bit is set when the txmulticastpackets gb counter reaches half of the maximum value or the maximum value. Access restriction applies. Clears on read. Self set to 1 on internal event. Value After Reset 0x0
  [10] TXUCGBPIS — MMC Transmit Unicast Good Bad Packet Counter Interrupt Status TXUCGBPIS. This bit is set when the txunicastpackets gb counter reaches half of the maximum value or the maximum value. Access restriction applies. Clears on read. Self set to 1 on internal event. Value After Reset 0x0
  [9] TX1024TMAXOCTGBPIS — MMC Transmit 1024 to Maximum Octet Good Bad Packet Counter Interrupt Status TX1024TMAXOCTGBPIS. This bit is set when the tx1024tomaxoctets gb counter reaches half of the maximum value or the maximum value. Access restriction applies. Clears on read. Self set to 1 on internal event. Value After Reset 0x0
  [8] TX512T1023OCTGBPIS — MMC Transmit 512 to 1023 Octet Good Bad Packet Counter Interrupt Status TX512T1023OCTGBPIS. This bit is set when the tx512to1023octets gb counter reaches half of the maximum value or the maximum value. Access restriction applies. Clears on read. Self set to 1 on internal event. Value After Reset 0x0
  [7] TX256T511OCTGBPIS — MMC Transmit 256 to 511 Octet Good Bad Packet Counter Interrupt Status TX256T511OCTGBPIS. This bit is set when the tx256to511octets gb counter reaches half of the maximum value or the maximum value. Access restriction applies. Clears on read. Self set to 1 on internal event. Value After Reset 0x0
  [6] TX128T255OCTGBPIS — MMC Transmit 128 to 255 Octet Good Bad Packet Counter Interrupt Status TX128T255OCTGBPIS. This bit is set when the tx128to255octets gb counter reaches half of the maximum value or the maximum value. Access restriction applies. Clears on read. Self set to 1 on internal event. Value After Reset 0x0
  [5] TX65T127OCTGBPIS — MMC Transmit 65 to 127 Octet Good Bad Packet Counter Interrupt Status TX65T127OCTGBPIS. This bit is set when the tx65to127octets gb counter reaches half the maximum value and also when it reaches the maximum value. Access restriction applies. Clears on read. Self set to 1 on internal event. Value After Reset 0x0
  [4] TX64OCTGBPIS — MMC Transmit 64 Octet Good Bad Packet Counter Interrupt Status TX64OCTGBPIS. This bit is set when the tx64octets gb counter reaches half of the maximum value or the maximum value. Access restriction applies. Clears on read. Self set to 1 on internal event. Value After Reset 0x0
  [3] TXMCGPIS — MMC Transmit Multicast Good Packet Counter Interrupt Status TXMCGPIS. This bit is set when the txmulticastpackets g counter reaches half of the maximum value or the maximum value. Access restriction applies. Clears on read. Self set to 1 on internal event. Value After Reset 0x0
  [2] TXBCGPIS — MMC Transmit Broadcast Good Packet Counter Interrupt Status TXBCGPIS. This bit is set when the txbroadcastpackets g counter reaches half of the maximum value or the maximum value. Access restriction applies. Clears on read. Self set to 1 on internal event. Value After Reset 0x0
  [1] TXGBPKTIS — MMC Transmit Good Bad Packet Counter Interrupt Status TXGBPKTIS. This bit is set when the txpacketcount gb counter reaches half of the maximum value or the maximum value. Access restriction applies. Clears on read. Self set to 1 on internal event. Value After Reset 0x0
  [0] TXGBOCTIS — MMC Transmit Good Bad Octet Counter Interrupt Status TXGBOCTIS. This bit is set when the txoctetcount gb counter reaches half of the maximum value or the maximum value. Access restriction applies. Clears on read. Self set to 1 on internal event. Value After Reset 0x0
0x70C MMC_RX_INTERRUPT_MASK — MMC Receive Interrupts Mask Register resetvalue={Application Reset:0x0}
  [27] RXLPITRCIM — MMC Receive LPI transition counter interrupt Mask RXLPITRCIM. Setting this bit masks the interrupt when the Rx LPI Tran Cntr counter reaches half of the maximum value or the maximum value. Value After Reset 0x0
  [26] RXLPIUSCIM — MMC Receive LPI microsecond counter interrupt Mask RXLPIUSCIM. Setting this bit masks the interrupt when the Rx LPI USEC Cntr counter reaches half of the maximum value or the maximum value. Value After Reset 0x0
  [25] RXCTRLPIM — MMC Receive Control Packet Counter Interrupt Mask RXCTRLPIM. Setting this bit masks the interrupt when the rxctrlpackets g counter reaches half of the maximum value or the maximum value. Value After Reset 0x0
  [24] RXRCVERRPIM — MMC Receive Error Packet Counter Interrupt Mask RXRCVERRPIM. Setting this bit masks the interrupt when the rxrcverror counter reaches half of the maximum value or the maximum value. Value After Reset 0x0
  [23] RXWDOGPIM — MMC Receive Watchdog Error Packet Counter Interrupt Mask RXWDOGPIM. Setting this bit masks the interrupt when the rxwatchdog counter reaches half of the maximum value or the maximum value. Value After Reset 0x0
  [22] RXVLANGBPIM — MMC Receive VLAN Good Bad Packet Counter Interrupt Mask RXVLANGBPIM. Setting this bit masks the interrupt when the rxvlanpackets gb counter reaches half of the maximum value or the maximum value. Value After Reset 0x0
  [21] RXFOVPIM — MMC Receive FIFO Overflow Packet Counter Interrupt Mask RXFOVPIM. Setting this bit masks the interrupt when the rxfifooverflow counter reaches half of the maximum value or the maximum value. Value After Reset 0x0
  [20] RXPAUSPIM — MMC Receive Pause Packet Counter Interrupt Mask RXPAUSPIM. Setting this bit masks the interrupt when the rxpausepackets counter reaches half of the maximum value or the maximum value. Value After Reset 0x0
  [19] RXORANGEPIM — MMC Receive Out Of Range Error Packet Counter Interrupt Mask RXORANGEPIM. Setting this bit masks the interrupt when the rxoutofrangetype counter reaches half of the maximum value or the maximum value. Value After Reset 0x0
  [18] RXLENERPIM — MMC Receive Length Error Packet Counter Interrupt Mask RXLENERPIM. Setting this bit masks the interrupt when the rxlengtherror counter reaches half of the maximum value or the maximum value. Value After Reset 0x0
  [17] RXUCGPIM — MMC Receive Unicast Good Packet Counter Interrupt Mask RXUCGPIM. Setting this bit masks the interrupt when the rxunicastpackets g counter reaches half of the maximum value or the maximum value. Value After Reset 0x0
  [16] RX1024TMAXOCTGBPIM — MMC Receive 1024 to Maximum Octet Good Bad Packet Counter Interrupt Mask. RX1024TMAXOCTGBPIM. Setting this bit masks the interrupt when the rx1024tomaxoctets gb counter reaches half of the maximum value or the maximum value. Value After Reset 0x0
  [15] RX512T1023OCTGBPIM — MMC Receive 512 to 1023 Octet Good Bad Packet Counter Interrupt Mask RX512T1023OCTGBPIM. Setting this bit masks the interrupt when the rx512to1023octets gb counter reaches half of the maximum value or the maximum value. Value After Reset 0x0
  [14] RX256T511OCTGBPIM — MMC Receive 256 to 511 Octet Good Bad Packet Counter Interrupt Mask RX256T511OCTGBPIM. Setting this bit masks the interrupt when the rx256to511octets gb counter reaches half of the maximum value or the maximum value. Value After Reset 0x0
  [13] RX128T255OCTGBPIM — MMC Receive 128 to 255 Octet Good Bad Packet Counter Interrupt Mask RX128T255OCTGBPIM. Setting this bit masks the interrupt when the rx128to255octets gb counter reaches half of the maximum value or the maximum value. Value After Reset 0x0
  [12] RX65T127OCTGBPIM — MMC Receive 65 to 127 Octet Good Bad Packet Counter Interrupt Mask RX65T127OCTGBPIM. Setting this bit masks the interrupt when the rx65to127octets gb counter reaches half of the maximum value or the maximum value. Value After Reset 0x0
  [11] RX64OCTGBPIM — MMC Receive 64 Octet Good Bad Packet Counter Interrupt Mask RX64OCTGBPIM. Setting this bit masks the interrupt when the rx64octets gb counter reaches half of the maximum value or the maximum value. Value After Reset 0x0
  [10] RXOSIZEGPIM — MMC Receive Oversize Good Packet Counter Interrupt Mask RXOSIZEGPIM. Setting this bit masks the interrupt when the rxoversize g counter reaches half of the maximum value or the maximum value. Value After Reset 0x0
  [9] RXUSIZEGPIM — MMC Receive Undersize Good Packet Counter Interrupt Mask RXUSIZEGPIM. Setting this bit masks the interrupt when the rxundersize g counter reaches half of the maximum value or the maximum value. Value After Reset 0x0
  [8] RXJABERPIM — MMC Receive Jabber Error Packet Counter Interrupt Mask RXJABERPIM. Setting this bit masks the interrupt when the rxjabbererror counter reaches half of the maximum value or the maximum value. Value After Reset 0x0
  [7] RXRUNTPIM — MMC Receive Runt Packet Counter Interrupt Mask RXRUNTPIM. Setting this bit masks the interrupt when the rxrunterror counter reaches half of the maximum value or the maximum value. Value After Reset 0x0
  [6] RXALGNERPIM — MMC Receive Alignment Error Packet Counter Interrupt Mask RXALGNERPIM. Setting this bit masks the interrupt when the rxalignmenterror counter reaches half of the maximum value or the maximum value. Value After Reset 0x0
  [5] RXCRCERPIM — MMC Receive CRC Error Packet Counter Interrupt Mask RXCRCERPIM. Setting this bit masks the interrupt when the rxcrcerror counter reaches half of the maximum value or the maximum value. Value After Reset 0x0
  [4] RXMCGPIM — MMC Receive Multicast Good Packet Counter Interrupt Mask RXMCGPIM. Setting this bit masks the interrupt when the rxmulticastpackets g counter reaches half of the maximum value or the maximum value. Value After Reset 0x0
  [3] RXBCGPIM — MMC Receive Broadcast Good Packet Counter Interrupt Mask RXBCGPIM. Setting this bit masks the interrupt when the rxbroadcastpackets g counter reaches half of the maximum value or the maximum value. Value After Reset 0x0
  [2] RXGOCTIM — MMC Receive Good Octet Counter Interrupt Mask RXGOCTIM. Setting this bit masks the interrupt when the rxoctetcount g counter reaches half of the maximum value or the maximum value. Value After Reset 0x0
  [1] RXGBOCTIM — MMC Receive Good Bad Octet Counter Interrupt Mask RXGBOCTIM. Setting this bit masks the interrupt when the rxoctetcount gb counter reaches half of the maximum value or the maximum value. Value After Reset 0x0
  [0] RXGBPKTIM — MMC Receive Good Bad Packet Counter Interrupt Mask RXGBPKTIM. Setting this bit masks the interrupt when the rxpacketcount gb counter reaches half of the maximum value or the maximum value. Value After Reset 0x0
